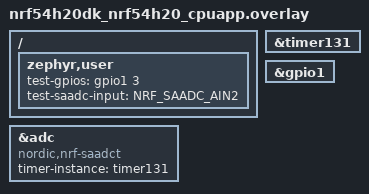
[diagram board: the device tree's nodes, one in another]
/*
 * Copyright (c) 2026 Nordic Semiconductor ASA
 *
 * SPDX-License-Identifier: LicenseRef-Nordic-5-Clause
 */

/*
 * Test requires loopback between P1.02 and P1.03
 */

/ {
	zephyr,user {
		test-gpios = <&gpio1 3 GPIO_ACTIVE_HIGH>;
		test-saadc-input = <NRF_SAADC_AIN2>; /* P1.02 */
	};
};

&timer131 {
	status = "okay";
};

&gpio1 {
	status = "okay";
};

&adc {
	compatible = "nordic,nrf-saadct";
	status = "okay";
	timer-instance = <&timer131>;
	#address-cells = <1>;
	#size-cells = <0>;
};
